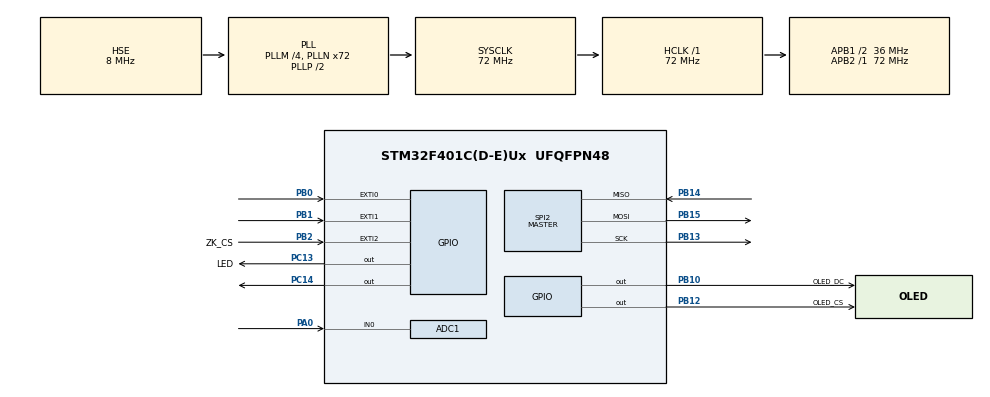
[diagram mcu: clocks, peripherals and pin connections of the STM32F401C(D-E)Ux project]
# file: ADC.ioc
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ADC1.Channel-0\#ChannelRegularConversion=ADC_CHANNEL_0
ADC1.ClockPrescaler=ADC_CLOCK_SYNC_PCLK_DIV2
ADC1.ContinuousConvMode=ENABLE
ADC1.EnableAnalogWatchDog=true
ADC1.HighThreshold=4090
ADC1.NbrOfConversion=1
ADC1.NbrOfConversionFlag=1
ADC1.Rank-0\#ChannelRegularConversion=1
ADC1.Resolution=ADC_RESOLUTION_12B
ADC1.SamplingTime-0\#ChannelRegularConversion=ADC_SAMPLETIME_3CYCLES
ADC1.ScanConvMode=DISABLE
ADC1.master=1
Mcu.Family=STM32F4
Mcu.Name=STM32F401C(D-E)Ux
Mcu.Package=UFQFPN48
NVIC.ADC_IRQn=true\:1\:0\:true\:false\:true\:true\:true
NVIC.EXTI0_IRQn=true\:2\:0\:true\:false\:true\:true\:true
NVIC.EXTI1_IRQn=true\:2\:0\:true\:false\:true\:true\:true
NVIC.EXTI2_IRQn=true\:2\:0\:true\:false\:true\:true\:true
NVIC.PriorityGroup=NVIC_PRIORITYGROUP_4
PA0-WKUP.Signal=SharedAnalog_PA0
PA13.Mode=Serial_Wire
PA13.Signal=SYS_JTMS-SWDIO
PA14.Mode=Serial_Wire
PA14.Signal=SYS_JTCK-SWCLK
PB0.GPIO_ModeDefaultEXTI=GPIO_MODE_IT_FALLING
PB0.Signal=GPXTI0
PB1.GPIO_ModeDefaultEXTI=GPIO_MODE_IT_FALLING
PB1.Signal=GPXTI1
PB10.GPIO_Label=OLED_DC
PB10.Signal=GPIO_Output
PB12.GPIO_Label=OLED_CS
PB12.Signal=GPIO_Output
PB13.Mode=Full_Duplex_Master
PB13.Signal=SPI2_SCK
PB14.Mode=Full_Duplex_Master
PB14.Signal=SPI2_MISO
PB15.Mode=Full_Duplex_Master
PB15.Signal=SPI2_MOSI
PB2.GPIO_Label=ZK_CS
PB2.GPIO_ModeDefaultEXTI=GPIO_MODE_IT_FALLING
PB2.Signal=GPXTI2
PC13-ANTI_TAMP.GPIO_Label=LED
PC13-ANTI_TAMP.Signal=GPIO_Output
PC14-OSC32_IN.Signal=GPIO_Output
PH0\ -\ OSC_IN.Mode=HSE-External-Oscillator
PH0\ -\ OSC_IN.Signal=RCC_OSC_IN
PH1\ -\ OSC_OUT.Mode=HSE-External-Oscillator
PH1\ -\ OSC_OUT.Signal=RCC_OSC_OUT
ProjectManager.HeapSize=0x200
ProjectManager.StackSize=0x400
ProjectManager.TargetToolchain=Makefile
RCC.48MHZClocksFreq_Value=36000000
RCC.AHBFreq_Value=72000000
RCC.APB1CLKDivider=RCC_HCLK_DIV2
RCC.APB1Freq_Value=36000000
RCC.APB1TimFreq_Value=72000000
RCC.APB2Freq_Value=72000000
RCC.APB2TimFreq_Value=72000000
RCC.CortexFreq_Value=72000000
RCC.HCLKFreq_Value=72000000
RCC.HSE_VALUE=8000000
RCC.HSI_VALUE=16000000
RCC.LSE_VALUE=32768
RCC.PLLM=4
RCC.PLLN=72
RCC.PLLSourceVirtual=RCC_PLLSOURCE_HSE
RCC.SYSCLKFreq_VALUE=72000000
RCC.SYSCLKSource=RCC_SYSCLKSOURCE_PLLCLK
RCC.VCOOutputFreq_Value=144000000
SH.SharedAnalog_PA0.0=GPIO_Analog
SH.SharedAnalog_PA0.1=ADC1_IN0,IN0
SPI2.BaudRatePrescaler=SPI_BAUDRATEPRESCALER_4
SPI2.Direction=SPI_DIRECTION_2LINES
SPI2.Mode=SPI_MODE_MASTER
SPI2.VirtualType=VM_MASTER
board=custom

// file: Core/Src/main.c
/* USER CODE BEGIN Header */
/**
 ******************************************************************************
 * @file           : main.c
 * @brief          : Main program body
 ******************************************************************************
 * @attention
 *
 * Copyright (c) 2022 STMicroelectronics.
 * All rights reserved.
 *
 * This software is licensed under terms that can be found in the LICENSE file
 * in the root directory of this software component.
 * If no LICENSE file comes with this software, it is provided AS-IS.
 *
 ******************************************************************************
 */
/* USER CODE END Header */
#include "main.h"
#include "adc.h"
#include "spi.h"
#include "gpio.h"

void SystemClock_Config(void);

int main(void)
{

  /* MCU Configuration--------------------------------------------------------*/

  /* Reset of all peripherals, Initializes the Flash interface and the Systick. */
  HAL_Init();

  /* Configure the system clock */
  SystemClock_Config();

  /* Initialize all configured peripherals */
  MX_GPIO_Init();
  MX_ADC1_Init();
  MX_SPI2_Init();
  /* USER CODE BEGIN 2 */
  HAL_ADC_Start_IT(&hadc1);
  InitGraph();
  // OLED_Rect1(0, 0, 127, 63);
  // OLED_Circle(25, 32, 20);
  // OLED_Circle(25, 32, 3);
  OLED_UpdateScreen();
  /* USER CODE END 2 */

  /* Infinite loop */
  /* USER CODE BEGIN WHILE */
  int i, k = 0;
  while (1)
  {
    HAL_GPIO_TogglePin(GPIOC, GPIO_PIN_13);
    HAL_Delay(1);
    // OLED_Circle(25, 32, 20);
    // SetPointBuffer(0, 0, 1);
    for (int j = 1; j < 128; j+=2)
    {
      i = result;
      // SetPointBuffer(j, i / 90, 1);
      OLED_Line(j - 1, k / 90, j, i / 90);
      OLED_UpdateScreen();
      k = i;
    }
    OLED_ClearScreen();
    /* USER CODE END WHILE */

  }
}

void SystemClock_Config(void)
{
  RCC_OscInitTypeDef RCC_OscInitStruct = {0};
  RCC_ClkInitTypeDef RCC_ClkInitStruct = {0};

  /** Configure the main internal regulator output voltage
  */
  __HAL_RCC_PWR_CLK_ENABLE();
  __HAL_PWR_VOLTAGESCALING_CONFIG(PWR_REGULATOR_VOLTAGE_SCALE2);
  /** Initializes the RCC Oscillators according to the specified parameters
  * in the RCC_OscInitTypeDef structure.
  */
  RCC_OscInitStruct.OscillatorType = RCC_OSCILLATORTYPE_HSE;
  RCC_OscInitStruct.HSEState = RCC_HSE_ON;
  RCC_OscInitStruct.PLL.PLLState = RCC_PLL_ON;
  RCC_OscInitStruct.PLL.PLLSource = RCC_PLLSOURCE_HSE;
  RCC_OscInitStruct.PLL.PLLM = 4;
  RCC_OscInitStruct.PLL.PLLN = 72;
  RCC_OscInitStruct.PLL.PLLP = RCC_PLLP_DIV2;
  RCC_OscInitStruct.PLL.PLLQ = 4;
  if (HAL_RCC_OscConfig(&RCC_OscInitStruct) != HAL_OK)
  {
    Error_Handler();
  }
  /** Initializes the CPU, AHB and APB buses clocks
  */
  RCC_ClkInitStruct.ClockType = RCC_CLOCKTYPE_HCLK|RCC_CLOCKTYPE_SYSCLK
                              |RCC_CLOCKTYPE_PCLK1|RCC_CLOCKTYPE_PCLK2;
  RCC_ClkInitStruct.SYSCLKSource = RCC_SYSCLKSOURCE_PLLCLK;
  RCC_ClkInitStruct.AHBCLKDivider = RCC_SYSCLK_DIV1;
  RCC_ClkInitStruct.APB1CLKDivider = RCC_HCLK_DIV2;
  RCC_ClkInitStruct.APB2CLKDivider = RCC_HCLK_DIV1;

  if (HAL_RCC_ClockConfig(&RCC_ClkInitStruct, FLASH_LATENCY_2) != HAL_OK)
  {
    Error_Handler();
  }
}

void Error_Handler(void)
{
  __disable_irq();
  while (1)
  {
  }
}
